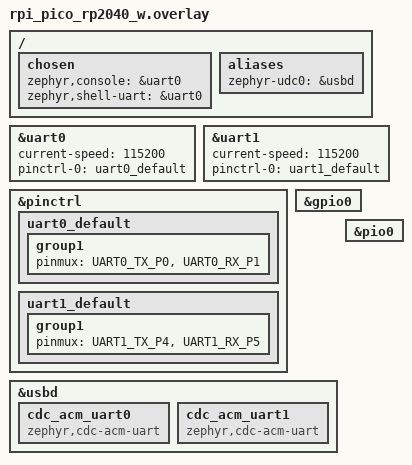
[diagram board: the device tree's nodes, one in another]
/*
 * SPDX-License-Identifier: MIT
 * Copyright (c) 2026 Vincent Jardin <vjardin@free.fr>
 *
 * Debugprobe Zephyr Port - Device Tree Overlay for Raspberry Pi Pico W
 *
 * Note: Pico W has the LED connected through the CYW43 WiFi chip,
 * not directly to GPIO 25 like the regular Pico.
 */

/ {
    chosen {
        zephyr,console = &uart0;
        zephyr,shell-uart = &uart0;
    };

    aliases {
        zephyr-udc0 = &usbd;
    };

};

/* Debug UART for console */
&uart0 {
    status = "okay";
    current-speed = <115200>;
    pinctrl-0 = <&uart0_default>;
    pinctrl-names = "default";
};

/* Bridge UART */
&uart1 {
    status = "okay";
    current-speed = <115200>;
    pinctrl-0 = <&uart1_default>;
    pinctrl-names = "default";
};

/* Pin control */
&pinctrl {
    uart0_default: uart0_default {
        group1 {
            pinmux = <UART0_TX_P0>, <UART0_RX_P1>;
        };
    };

    uart1_default: uart1_default {
        group1 {
            pinmux = <UART1_TX_P4>, <UART1_RX_P5>;
        };
    };
};

/* GPIO for SWD pins */
&gpio0 {
    status = "okay";
};

/* USB Device with CDC ACM */
&usbd {
    status = "okay";

    /* CDC ACM #0 - available for host communication */
    cdc_acm_uart0: cdc_acm_uart0 {
        compatible = "zephyr,cdc-acm-uart";
    };

    /* CDC ACM #1 - UART bridge to target */
    cdc_acm_uart1: cdc_acm_uart1 {
        compatible = "zephyr,cdc-acm-uart";
    };
};

/* PIO for high-speed SWD */
&pio0 {
    status = "okay";
};
